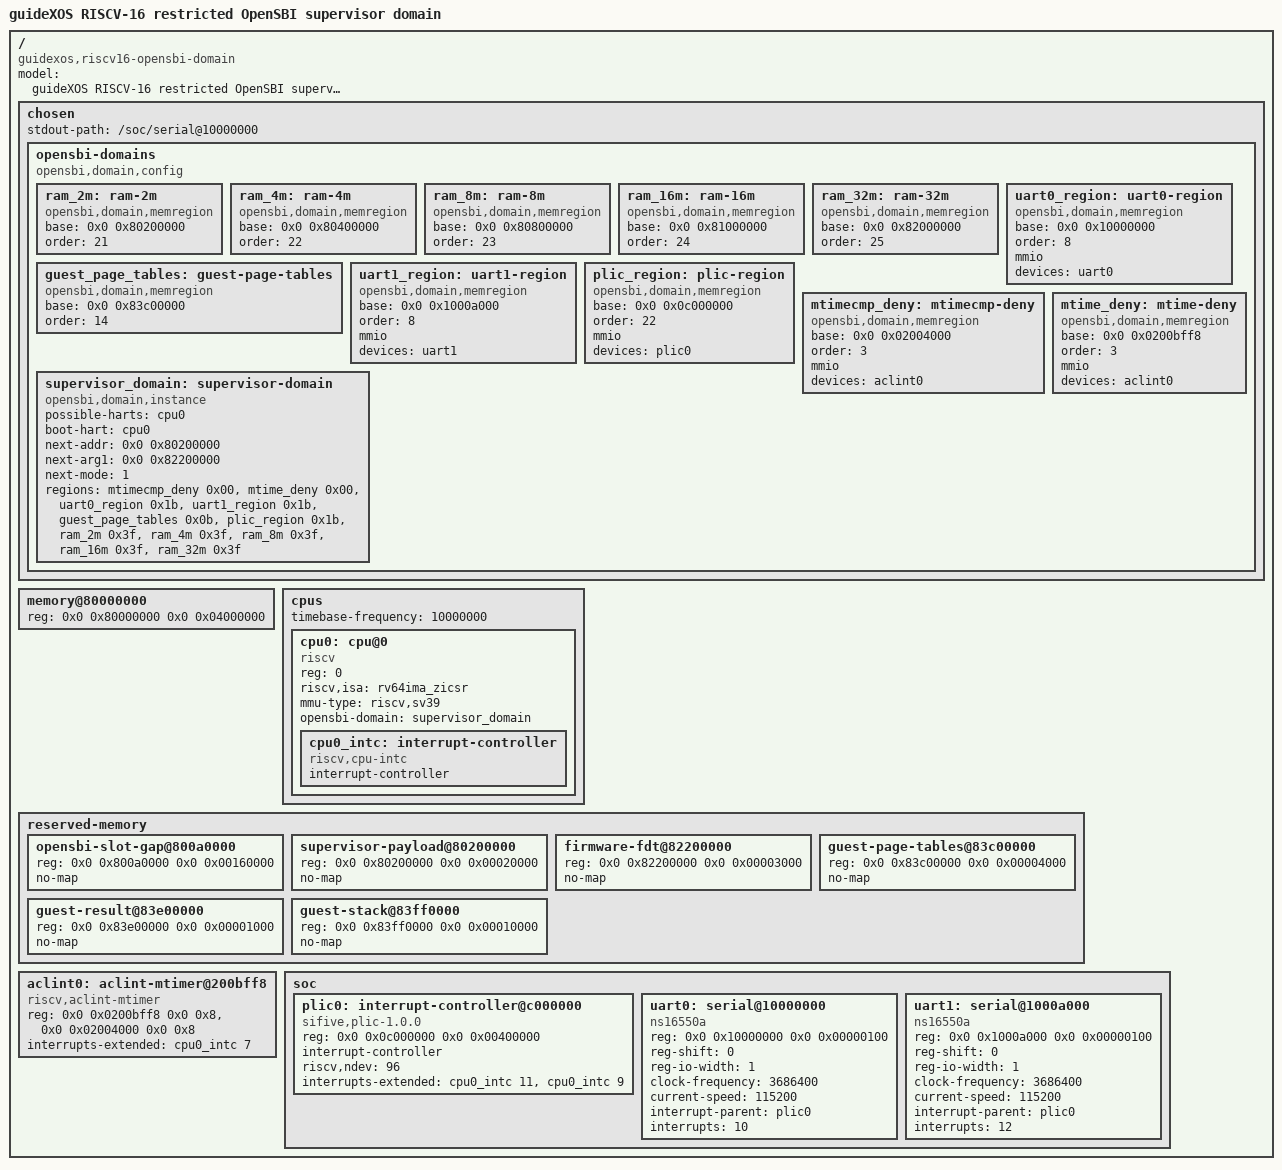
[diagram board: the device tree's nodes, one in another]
/dts-v1/;

/ {
	model = "guideXOS RISCV-16 restricted OpenSBI supervisor domain";
	compatible = "guidexos,riscv16-opensbi-domain";
	#address-cells = <2>;
	#size-cells = <2>;

	chosen {
		stdout-path = "/soc/serial@10000000";

		opensbi-domains {
			compatible = "opensbi,domain,config";

			ram_2m: ram-2m {
				compatible = "opensbi,domain,memregion";
				base = <0x0 0x80200000>;
				order = <21>;
			};
			ram_4m: ram-4m {
				compatible = "opensbi,domain,memregion";
				base = <0x0 0x80400000>;
				order = <22>;
			};
			ram_8m: ram-8m {
				compatible = "opensbi,domain,memregion";
				base = <0x0 0x80800000>;
				order = <23>;
			};
			ram_16m: ram-16m {
				compatible = "opensbi,domain,memregion";
				base = <0x0 0x81000000>;
				order = <24>;
			};
			ram_32m: ram-32m {
				compatible = "opensbi,domain,memregion";
				base = <0x0 0x82000000>;
				order = <25>;
			};

			guest_page_tables: guest-page-tables {
				compatible = "opensbi,domain,memregion";
				base = <0x0 0x83c00000>;
				order = <14>;
			};

			uart0_region: uart0-region {
				compatible = "opensbi,domain,memregion";
				base = <0x0 0x10000000>;
				order = <8>;
				mmio;
				devices = <&uart0>;
			};
			uart1_region: uart1-region {
				compatible = "opensbi,domain,memregion";
				base = <0x0 0x1000a000>;
				order = <8>;
				mmio;
				devices = <&uart1>;
			};
			plic_region: plic-region {
				compatible = "opensbi,domain,memregion";
				base = <0x0 0x0c000000>;
				order = <22>;
				mmio;
				devices = <&plic0>;
			};

			mtimecmp_deny: mtimecmp-deny {
				compatible = "opensbi,domain,memregion";
				base = <0x0 0x02004000>;
				order = <3>;
				mmio;
				devices = <&aclint0>;
			};
			mtime_deny: mtime-deny {
				compatible = "opensbi,domain,memregion";
				base = <0x0 0x0200bff8>;
				order = <3>;
				mmio;
				devices = <&aclint0>;
			};

			supervisor_domain: supervisor-domain {
				compatible = "opensbi,domain,instance";
				possible-harts = <&cpu0>;
				boot-hart = <&cpu0>;
				next-addr = <0x0 0x80200000>;
				next-arg1 = <0x0 0x82200000>;
				next-mode = <1>;
				regions = <&mtimecmp_deny 0x00>, <&mtime_deny 0x00>,
					  <&uart0_region 0x1b>, <&uart1_region 0x1b>,
					  <&guest_page_tables 0x0b>, <&plic_region 0x1b>,
					  <&ram_2m 0x3f>, <&ram_4m 0x3f>,
					  <&ram_8m 0x3f>, <&ram_16m 0x3f>,
					  <&ram_32m 0x3f>;
			};
		};
	};

	memory@80000000 {
		device_type = "memory";
		reg = <0x0 0x80000000 0x0 0x04000000>;
	};

	cpus {
		#address-cells = <1>;
		#size-cells = <0>;
		timebase-frequency = <10000000>;

		cpu0: cpu@0 {
			device_type = "cpu";
			compatible = "riscv";
			reg = <0>;
			status = "okay";
			riscv,isa = "rv64ima_zicsr";
			mmu-type = "riscv,sv39";
			opensbi-domain = <&supervisor_domain>;

			cpu0_intc: interrupt-controller {
				compatible = "riscv,cpu-intc";
				interrupt-controller;
				#interrupt-cells = <1>;
				phandle = <1>;
			};
		};
	};

	reserved-memory {
		#address-cells = <2>;
		#size-cells = <2>;
		ranges;

		opensbi-slot-gap@800a0000 {
			reg = <0x0 0x800a0000 0x0 0x00160000>;
			no-map;
		};
		supervisor-payload@80200000 {
			reg = <0x0 0x80200000 0x0 0x00020000>;
			no-map;
		};
		firmware-fdt@82200000 {
			reg = <0x0 0x82200000 0x0 0x00003000>;
			no-map;
		};
		guest-page-tables@83c00000 {
			reg = <0x0 0x83c00000 0x0 0x00004000>;
			no-map;
		};
		guest-result@83e00000 {
			reg = <0x0 0x83e00000 0x0 0x00001000>;
			no-map;
		};
		guest-stack@83ff0000 {
			reg = <0x0 0x83ff0000 0x0 0x00010000>;
			no-map;
		};
	};

	/* Both comparator and time counter remain machine-owned. */
	aclint0: aclint-mtimer@200bff8 {
		compatible = "riscv,aclint-mtimer";
		reg = <0x0 0x0200bff8 0x0 0x8>,
		      <0x0 0x02004000 0x0 0x8>;
		reg-names = "mtime", "mtimecmp";
		interrupts-extended = <&cpu0_intc 7>;
		status = "okay";
	};

	soc {
		#address-cells = <2>;
		#size-cells = <2>;
		ranges;

		plic0: interrupt-controller@c000000 {
			compatible = "sifive,plic-1.0.0", "riscv,plic0";
			reg = <0x0 0x0c000000 0x0 0x00400000>;
			#interrupt-cells = <1>;
			interrupt-controller;
			riscv,ndev = <96>;
			phandle = <2>;
			interrupts-extended = <&cpu0_intc 11>, <&cpu0_intc 9>;
			status = "okay";
		};

		uart0: serial@10000000 {
			compatible = "ns16550a", "ns16550";
			reg = <0x0 0x10000000 0x0 0x00000100>;
			reg-shift = <0>;
			reg-io-width = <1>;
			clock-frequency = <3686400>;
			current-speed = <115200>;
			interrupt-parent = <&plic0>;
			interrupts = <10>;
			status = "okay";
		};

		uart1: serial@1000a000 {
			compatible = "ns16550a", "ns16550";
			reg = <0x0 0x1000a000 0x0 0x00000100>;
			reg-shift = <0>;
			reg-io-width = <1>;
			clock-frequency = <3686400>;
			current-speed = <115200>;
			interrupt-parent = <&plic0>;
			interrupts = <12>;
			status = "okay";
		};
	};
};
